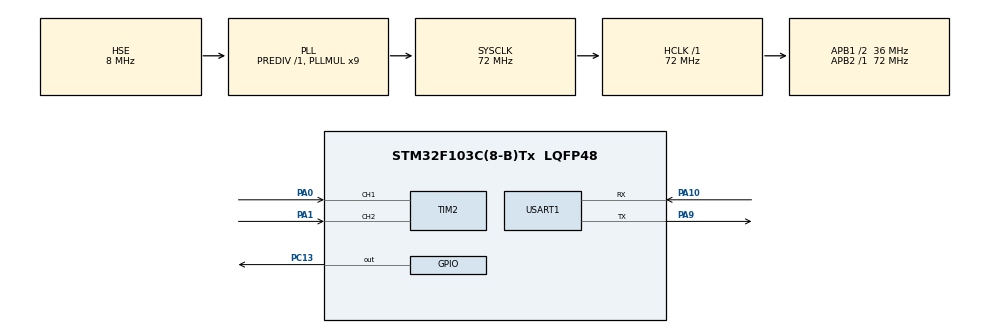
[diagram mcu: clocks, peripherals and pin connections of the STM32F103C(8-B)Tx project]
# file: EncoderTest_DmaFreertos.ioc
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Dma.Request0=USART1_TX
Dma.USART1_TX.0.Direction=DMA_MEMORY_TO_PERIPH
Dma.USART1_TX.0.Instance=DMA1_Channel4
Dma.USART1_TX.0.MemDataAlignment=DMA_MDATAALIGN_BYTE
Dma.USART1_TX.0.MemInc=DMA_MINC_ENABLE
Dma.USART1_TX.0.Mode=DMA_CIRCULAR
Dma.USART1_TX.0.PeriphDataAlignment=DMA_PDATAALIGN_BYTE
Dma.USART1_TX.0.PeriphInc=DMA_PINC_DISABLE
Dma.USART1_TX.0.Priority=DMA_PRIORITY_MEDIUM
FREERTOS.Tasks01=defaultTask,24,128,StartDefaultTask,Default,NULL,Dynamic,NULL,NULL
Mcu.Family=STM32F1
Mcu.Name=STM32F103C(8-B)Tx
Mcu.Package=LQFP48
NVIC.DMA1_Channel4_IRQn=true\:5\:0\:false\:false\:true\:true\:false\:true\:true
NVIC.PriorityGroup=NVIC_PRIORITYGROUP_4
NVIC.TIM2_IRQn=true\:5\:0\:false\:false\:true\:true\:true\:true\:true
NVIC.TIM4_IRQn=true\:15\:0\:false\:false\:true\:false\:true\:true\:true
NVIC.TimeBase=TIM4_IRQn
NVIC.TimeBaseIP=TIM4
NVIC.USART1_IRQn=true\:5\:0\:false\:false\:true\:true\:false\:true\:true
PA0-WKUP.Signal=S_TIM2_CH1_ETR
PA1.Signal=S_TIM2_CH2
PA10.Mode=Asynchronous
PA10.Signal=USART1_RX
PA13.Mode=Serial_Wire
PA13.Signal=SYS_JTMS-SWDIO
PA14.Mode=Serial_Wire
PA14.Signal=SYS_JTCK-SWCLK
PA9.Mode=Asynchronous
PA9.Signal=USART1_TX
PC13-TAMPER-RTC.PinState=GPIO_PIN_SET
PC13-TAMPER-RTC.Signal=GPIO_Output
PD0-OSC_IN.Mode=HSE-External-Oscillator
PD0-OSC_IN.Signal=RCC_OSC_IN
PD1-OSC_OUT.Mode=HSE-External-Oscillator
PD1-OSC_OUT.Signal=RCC_OSC_OUT
ProjectManager.HeapSize=0x200
ProjectManager.StackSize=0x400
ProjectManager.TargetToolchain=MDK-ARM V5.32
RCC.AHBFreq_Value=72000000
RCC.APB1CLKDivider=RCC_HCLK_DIV2
RCC.APB1Freq_Value=36000000
RCC.APB1TimFreq_Value=72000000
RCC.APB2Freq_Value=72000000
RCC.APB2TimFreq_Value=72000000
RCC.EnbaleCSS=true
RCC.HCLKFreq_Value=72000000
RCC.PLLMUL=RCC_PLL_MUL9
RCC.PLLSourceVirtual=RCC_PLLSOURCE_HSE
RCC.SYSCLKFreq_VALUE=72000000
RCC.SYSCLKSource=RCC_SYSCLKSOURCE_PLLCLK
RCC.USBFreq_Value=72000000
SH.S_TIM2_CH1_ETR.0=TIM2_CH1,Encoder_Interface
SH.S_TIM2_CH2.0=TIM2_CH2,Encoder_Interface
USART1.VirtualMode=VM_ASYNC
VP_FREERTOS_VS_CMSIS_V2.Mode=CMSIS_V2
VP_SYS_VS_tim4.Mode=TIM4
board=custom

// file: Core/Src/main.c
/* USER CODE BEGIN Header */
/**
  ******************************************************************************
  * @file           : main.c
  * @brief          : Main program body
  ******************************************************************************
  * @attention
  *
  * Copyright (c) 2025 STMicroelectronics.
  * All rights reserved.
  *
  * This software is licensed under terms that can be found in the LICENSE file
  * in the root directory of this software component.
  * If no LICENSE file comes with this software, it is provided AS-IS.
  *
  ******************************************************************************
  */
/* USER CODE END Header */
#include "main.h"
#include "cmsis_os.h"
#include "dma.h"
#include "tim.h"
#include "usart.h"
#include "gpio.h"

/* USER CODE BEGIN Includes */

#include "stdio.h"

/* USER CODE END Includes */

/* USER CODE BEGIN PV */

uint8_t tx_buf[50];   // 串口发送缓冲
int16_t last_cnt = 0;
// int16_t speed = 0;

/* USER CODE END PV */

void SystemClock_Config(void);
void MX_FREERTOS_Init(void);

int main(void)
{

  /* MCU Configuration--------------------------------------------------------*/

  /* Reset of all peripherals, Initializes the Flash interface and the Systick. */
  HAL_Init();

  /* Configure the system clock */
  SystemClock_Config();

  /* Initialize all configured peripherals */
  MX_GPIO_Init();
  MX_DMA_Init();
  MX_TIM2_Init();
  MX_USART1_UART_Init();
  /* USER CODE BEGIN 2 */

  HAL_TIM_Encoder_Start(&htim2, TIM_CHANNEL_ALL);
  HAL_TIM_Base_Start_IT(&htim4);

  /* USER CODE END 2 */

  /* Init scheduler */
  osKernelInitialize();  /* Call init function for freertos objects (in cmsis_os2.c) */
  MX_FREERTOS_Init();

  /* Start scheduler */
  osKernelStart();

  /* We should never get here as control is now taken by the scheduler */

  /* Infinite loop */
  while (1)
  {

  }
}

void SystemClock_Config(void)
{
  RCC_OscInitTypeDef RCC_OscInitStruct = {0};
  RCC_ClkInitTypeDef RCC_ClkInitStruct = {0};

  /** Initializes the RCC Oscillators according to the specified parameters
  * in the RCC_OscInitTypeDef structure.
  */
  RCC_OscInitStruct.OscillatorType = RCC_OSCILLATORTYPE_HSE;
  RCC_OscInitStruct.HSEState = RCC_HSE_ON;
  RCC_OscInitStruct.HSEPredivValue = RCC_HSE_PREDIV_DIV1;
  RCC_OscInitStruct.HSIState = RCC_HSI_ON;
  RCC_OscInitStruct.PLL.PLLState = RCC_PLL_ON;
  RCC_OscInitStruct.PLL.PLLSource = RCC_PLLSOURCE_HSE;
  RCC_OscInitStruct.PLL.PLLMUL = RCC_PLL_MUL9;
  if (HAL_RCC_OscConfig(&RCC_OscInitStruct) != HAL_OK)
  {
    Error_Handler();
  }

  /** Initializes the CPU, AHB and APB buses clocks
  */
  RCC_ClkInitStruct.ClockType = RCC_CLOCKTYPE_HCLK|RCC_CLOCKTYPE_SYSCLK
                              |RCC_CLOCKTYPE_PCLK1|RCC_CLOCKTYPE_PCLK2;
  RCC_ClkInitStruct.SYSCLKSource = RCC_SYSCLKSOURCE_PLLCLK;
  RCC_ClkInitStruct.AHBCLKDivider = RCC_SYSCLK_DIV1;
  RCC_ClkInitStruct.APB1CLKDivider = RCC_HCLK_DIV2;
  RCC_ClkInitStruct.APB2CLKDivider = RCC_HCLK_DIV1;

  if (HAL_RCC_ClockConfig(&RCC_ClkInitStruct, FLASH_LATENCY_2) != HAL_OK)
  {
    Error_Handler();
  }

  /** Enables the Clock Security System
  */
  HAL_RCC_EnableCSS();
}

/* USER CODE BEGIN 4 */

void HAL_TIM_PeriodElapsedCallback(TIM_HandleTypeDef *htim)
{
  if (htim->Instance == TIM4)
  {
    int16_t now = (int16_t)__HAL_TIM_GET_COUNTER(&htim2);
    int16_t speed = now - last_cnt;
    last_cnt = now;

    HAL_GPIO_TogglePin(GPIOC, GPIO_PIN_13);

    int len = sprintf((char *)tx_buf, "cnt,speed: %d,%d\r\n", now, speed);

    // ✅ 改为DMA发送（非阻塞）
    if (huart1.gState == HAL_UART_STATE_READY)
    {
        HAL_UART_Transmit_DMA(&huart1, tx_buf, len);
    }
    // 若还未发送完上一帧，则跳过本次
  }
}

// void HAL_UART_TxCpltCallback(UART_HandleTypeDef *huart)
// {
//   if (huart->Instance == USART1)
//   {
//     // 可选：发送完成后闪灯提示
//     HAL_GPIO_TogglePin(GPIOC, GPIO_PIN_13);
//   }
// }

/* USER CODE END 4 */

void HAL_TIM_PeriodElapsedCallback(TIM_HandleTypeDef *htim)
{
  if (htim->Instance == TIM4)
  {
    HAL_IncTick();
  }
}

void Error_Handler(void)
{
  __disable_irq();
  while (1)
  {
  }
}
